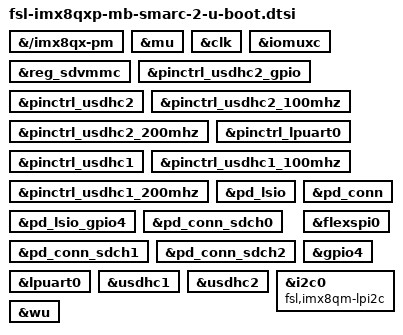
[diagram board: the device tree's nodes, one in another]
// SPDX-License-Identifier: GPL-2.0+
/*
 * Copyright 2018 - 2020 TQ Systems GmbH
 */

&{/imx8qx-pm} {

	u-boot,dm-spl;
};

&mu {
	u-boot,dm-spl;
};

&clk {
	u-boot,dm-spl;
};

&iomuxc {
	u-boot,dm-spl;
};

&reg_sdvmmc {
	u-boot,dm-spl;
};

&pinctrl_usdhc2_gpio {
	u-boot,dm-spl;
};

&pinctrl_usdhc2 {
	u-boot,dm-spl;
};

&pinctrl_usdhc2_100mhz {
	u-boot,dm-spl;
};

&pinctrl_usdhc2_200mhz {
	u-boot,dm-spl;
};

&pinctrl_lpuart0 {
	u-boot,dm-spl;
};

&pinctrl_usdhc1 {
	u-boot,dm-spl;
};

&pinctrl_usdhc1_100mhz {
	u-boot,dm-spl;
};

&pinctrl_usdhc1_200mhz {
	u-boot,dm-spl;
};

&pd_lsio {
	u-boot,dm-spl;
};

&pd_lsio_gpio4 {
	u-boot,dm-spl;
};

&pd_conn {
	u-boot,dm-spl;
};

&pd_conn_sdch0 {
	u-boot,dm-spl;
};

&pd_conn_sdch1 {
	u-boot,dm-spl;
};

&pd_conn_sdch2 {
	u-boot,dm-spl;
};

&flexspi0 {
	u-boot,dm-spl;
};

&gpio4 {
	u-boot,dm-spl;
};

&lpuart0 {
	u-boot,dm-spl;
};

&usdhc1 {
	u-boot,dm-spl;
};

&usdhc2 {
	u-boot,dm-spl;
};

&i2c0 {
	compatible = "fsl,imx8qm-lpi2c", "fsl,imx-virt-i2c";
};

&wu {
	u-boot,dm-spl;
};
